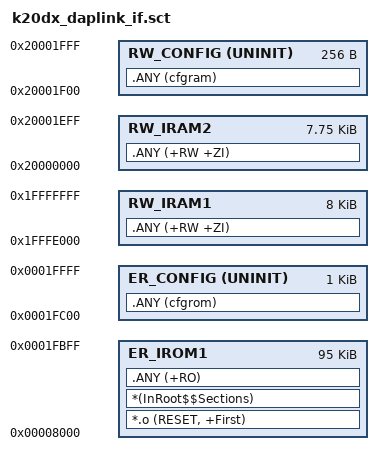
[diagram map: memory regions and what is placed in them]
LR_IROM1 0x00008000 0x17C00  {    ; load region size_region (96k - 1k)

  ER_IROM1 0x00008000 0x17C00  {  ; load address = execution address
   *.o (RESET, +First)
   *(InRoot$$Sections)
   .ANY (+RO)
  }
  
  RW_IRAM1 0x1FFFE000 0x00002000  {  ; RW data
   .ANY (+RW +ZI)
  }
  
  RW_IRAM2 0x20000000 0x00001F00  {
   .ANY (+RW +ZI)
  }

  RW_CONFIG 0x20001F00 UNINIT 0x100 {
    .ANY (cfgram)
  }
}
LR_CONFIG 0x0001FC00 0x400 {	 ; reserve last sector for config data
  ER_CONFIG 0x0001FC00 UNINIT 0x400 {
    .ANY (cfgrom)
  }
}
